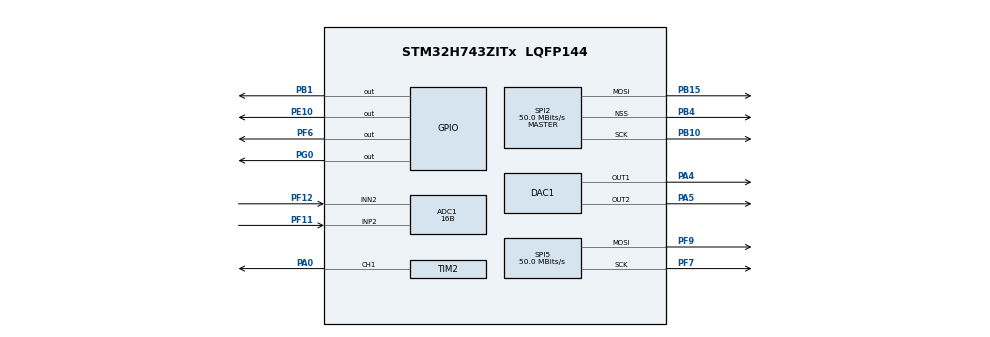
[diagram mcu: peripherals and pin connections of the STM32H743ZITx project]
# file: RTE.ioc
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ADC1.Channel-0\#ChannelRegularConversion=ADC_CHANNEL_2
ADC1.ClockPrescaler=ADC_CLOCK_ASYNC_DIV2
ADC1.ContinuousConvMode=ENABLE
ADC1.ConversionDataManagement=ADC_CONVERSIONDATA_DR
ADC1.DiscontinuousConvMode=DISABLE
ADC1.EOCSelection=ADC_EOC_SINGLE_CONV
ADC1.EnableAnalogWatchDog1=false
ADC1.EnableAnalogWatchDog2=false
ADC1.EnableAnalogWatchDog3=false
ADC1.EnableInjectedConversion=DISABLE
ADC1.EnableRegularConversion=ENABLE
ADC1.ExternalTrigConv=ADC_SOFTWARE_START
ADC1.ExternalTrigConvEdge=ADC_EXTERNALTRIGCONVEDGE_NONE
ADC1.LeftBitShift=ADC_LEFTBITSHIFT_NONE
ADC1.LowPowerAutoWait=DISABLE
ADC1.NbrOfConversion=1
ADC1.NbrOfConversionFlag=1
ADC1.OffsetNumber-0\#ChannelRegularConversion=ADC_OFFSET_NONE
ADC1.Overrun=ADC_OVR_DATA_PRESERVED
ADC1.OversamplingMode=DISABLE
ADC1.Rank-0\#ChannelRegularConversion=1
ADC1.Resolution=ADC_RESOLUTION_16B
ADC1.SamplingTime-0\#ChannelRegularConversion=ADC_SAMPLETIME_1CYCLE_5
ADC1.ScanConvMode=ADC_SCAN_DISABLE
ADC1.SingleDiff-0\#ChannelRegularConversion=ADC_DIFFERENTIAL_ENDED
ADC1.master=1
CORTEX_M7.CPU_DCache=Disabled
DAC1.DAC_Channel-DAC_OUT1=DAC_CHANNEL_1
DAC1.DAC_Channel-DAC_OUT2=DAC_CHANNEL_2
DAC1.DAC_Trigger-DAC_OUT1=DAC_TRIGGER_T2_TRGO
DAC1.DAC_Trigger-DAC_OUT2=DAC_TRIGGER_T2_TRGO
Mcu.Family=STM32H7
Mcu.Name=STM32H743ZITx
Mcu.Package=LQFP144
NVIC.PriorityGroup=NVIC_PRIORITYGROUP_4
NVIC.TIM2_IRQn=true\:0\:0\:true\:false\:true\:true\:true
PA0.Signal=S_TIM2_CH1
PA13\ (JTMS/SWDIO).Mode=Serial_Wire
PA13\ (JTMS/SWDIO).Signal=DEBUG_JTMS-SWDIO
PA14\ (JTCK/SWCLK).Mode=Serial_Wire
PA14\ (JTCK/SWCLK).Signal=DEBUG_JTCK-SWCLK
PA4.Signal=COMP_DAC11_group
PA5.Signal=COMP_DAC12_group
PB1.GPIO_ModeDefaultOutputPP=GPIO_MODE_OUTPUT_PP
PB1.GPIO_PuPd=GPIO_PULLDOWN
PB1.GPIO_Speed=GPIO_SPEED_FREQ_VERY_HIGH
PB1.Signal=GPIO_Output
PB10.Mode=TX_Only_Simplex_Unidirect_Master
PB10.Signal=SPI2_SCK
PB15.Mode=TX_Only_Simplex_Unidirect_Master
PB15.Signal=SPI2_MOSI
PB4\ (NJTRST).Mode=NSS_Signal_Hard_Output
PB4\ (NJTRST).Signal=SPI2_NSS
PE10.PinState=GPIO_PIN_SET
PE10.Signal=GPIO_Output
PF11.Mode=IN2-Differential
PF11.Signal=ADC1_INP2
PF12.Mode=IN2-Differential
PF12.Signal=ADC1_INN2
PF6.GPIO_Speed=GPIO_SPEED_FREQ_VERY_HIGH
PF6.Signal=GPIO_Output
PF7.Mode=TX_Only_Simplex_Unidirect_Master
PF7.Signal=SPI5_SCK
PF9.Mode=TX_Only_Simplex_Unidirect_Master
PF9.Signal=SPI5_MOSI
PG0.Signal=GPIO_Output
PH0-OSC_IN\ (PH0).Mode=HSE-External-Oscillator
PH0-OSC_IN\ (PH0).Signal=RCC_OSC_IN
PH1-OSC_OUT\ (PH1).Mode=HSE-External-Oscillator
PH1-OSC_OUT\ (PH1).Signal=RCC_OSC_OUT
ProjectManager.HeapSize=0x3000
ProjectManager.StackSize=0x400
ProjectManager.TargetToolchain=Makefile
RCC.ADCCLockSelection=RCC_ADCCLKSOURCE_PLL3
RCC.ADCFreq_Value=66666666.666666664
RCC.APB1Freq_Value=100000000
RCC.APB2Freq_Value=100000000
RCC.APB3Freq_Value=100000000
RCC.APB4Freq_Value=100000000
RCC.CortexFreq_Value=400000000
RCC.D1PPRE=RCC_APB3_DIV2
RCC.D2PPRE1=RCC_APB1_DIV2
RCC.D2PPRE2=RCC_APB2_DIV2
RCC.D3PPRE=RCC_APB4_DIV2
RCC.DIVM1=1
RCC.DIVM2=1
RCC.DIVM3=1
RCC.DIVN1=100
RCC.DIVN2=19
RCC.DIVN3=25
RCC.DIVP3=1
RCC.DIVR3=3
RCC.HCLKFreq_Value=200000000
RCC.HPRE=RCC_HCLK_DIV2
RCC.HSE_VALUE=8000000
RCC.PLL3FRACN=0
RCC.PLLFRACN=0
RCC.PLLSourceVirtual=RCC_PLLSOURCE_HSE
RCC.PWR_Regulator_Voltage_Scale=PWR_REGULATOR_VOLTAGE_SCALE1
RCC.RCC_TIM_PRescaler_Selection=RCC_TIMPRES_ACTIVATED
RCC.SPI123CLockSelection=RCC_SPI123CLKSOURCE_PLL3
RCC.SYSCLKFreq_VALUE=400000000
RCC.SYSCLKSource=RCC_SYSCLKSOURCE_PLLCLK
RCC.Spi45ClockSelection=RCC_SPI45CLKSOURCE_PLL3
RCC.USART234578CLockSelection=RCC_USART234578CLKSOURCE_PLL3
RCC.USBFreq_Value=400000000
SH.COMP_DAC11_group.0=DAC1_OUT1,DAC_OUT1
SH.COMP_DAC12_group.0=DAC1_OUT2,DAC_OUT2
SH.S_TIM2_CH1.0=TIM2_CH1,PWM Generation1 CH1
SPI2.BaudRatePrescaler=SPI_BAUDRATEPRESCALER_4
SPI2.CalculateBaudRate=50.0 MBits/s
SPI2.DataSize=SPI_DATASIZE_16BIT
SPI2.Direction=SPI_DIRECTION_2LINES_TXONLY
SPI2.MasterInterDataIdleness=SPI_MASTER_INTERDATA_IDLENESS_02CYCLE
SPI2.Mode=SPI_MODE_MASTER
SPI2.VirtualNSS=VM_NSSHARD
SPI2.VirtualType=VM_MASTER
SPI5.CLKPhase=SPI_PHASE_2EDGE
SPI5.CalculateBaudRate=50.0 MBits/s
SPI5.DataSize=SPI_DATASIZE_16BIT
SPI5.Direction=SPI_DIRECTION_2LINES_TXONLY
SPI5.MasterInterDataIdleness=SPI_MASTER_INTERDATA_IDLENESS_02CYCLE
SPI5.Mode=SPI_MODE_MASTER
SPI5.VirtualType=VM_MASTER
TIM2.Channel-PWM\ Generation1\ CH1=TIM_CHANNEL_1
TIM2.Pulse-PWM\ Generation1\ CH1=2
TIM2.TIM_MasterOutputTrigger=TIM_TRGO_UPDATE
VP_TIM2_VS_ClockSourceINT.Mode=Internal
board=custom

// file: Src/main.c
/* USER CODE BEGIN Header */
/**
 ******************************************************************************
 * @file           : main.c
 * @brief          : Main program body
 ******************************************************************************
 * @attention
 *
 * <h2><center>&copy; Copyright (c) 2021 STMicroelectronics.
 * All rights reserved.</center></h2>
 *
 * This software component is licensed by ST under BSD 3-Clause license,
 * the "License"; You may not use this file except in compliance with the
 * License. You may obtain a copy of the License at:
 *                        opensource.org/licenses/BSD-3-Clause
 *
 ******************************************************************************
 */
/* USER CODE END Header */
#include "main.h"
#include "adc.h"
#include "dac.h"
#include "gpio.h"
#include "spi.h"
#include "tim.h"

void SystemClock_Config(void);
void PeriphCommonClock_Config(void);

/* USER CODE BEGIN 0 */
void application();
void application_interupt();
void HAL_TIM_PeriodElapsedCallback(TIM_HandleTypeDef* htim)
{
    application_interupt();
}
/* USER CODE END 0 */

int main(void)
{

    /* MCU Configuration--------------------------------------------------------*/

    /* Reset of all peripherals, Initializes the Flash interface and the Systick. */
    HAL_Init();

    /* Configure the system clock */
    SystemClock_Config();

    /* Configure the peripherals common clocks */
    PeriphCommonClock_Config();

    /* Initialize all configured peripherals */
    MX_GPIO_Init();
    MX_DAC1_Init();
    MX_ADC1_Init();
    MX_TIM2_Init();
    MX_SPI2_Init();
    MX_SPI5_Init();
    /* USER CODE BEGIN 2 */
    application();
    /* USER CODE END 2 */

    /* Infinite loop */
    while (1) {

    }
}

void SystemClock_Config(void)
{
    RCC_OscInitTypeDef RCC_OscInitStruct = {0};
    RCC_ClkInitTypeDef RCC_ClkInitStruct = {0};

    /** Supply configuration update enable
     */
    HAL_PWREx_ConfigSupply(PWR_LDO_SUPPLY);
    /** Configure the main internal regulator output voltage
     */
    __HAL_PWR_VOLTAGESCALING_CONFIG(PWR_REGULATOR_VOLTAGE_SCALE1);

    while (!__HAL_PWR_GET_FLAG(PWR_FLAG_VOSRDY)) {
    }
    /** Macro to configure the PLL clock source
     */
    __HAL_RCC_PLL_PLLSOURCE_CONFIG(RCC_PLLSOURCE_HSE);
    /** Initializes the RCC Oscillators according to the specified parameters
     * in the RCC_OscInitTypeDef structure.
     */
    RCC_OscInitStruct.OscillatorType = RCC_OSCILLATORTYPE_HSE;
    RCC_OscInitStruct.HSEState       = RCC_HSE_ON;
    RCC_OscInitStruct.PLL.PLLState   = RCC_PLL_ON;
    RCC_OscInitStruct.PLL.PLLSource  = RCC_PLLSOURCE_HSE;
    RCC_OscInitStruct.PLL.PLLM       = 1;
    RCC_OscInitStruct.PLL.PLLN       = 100;
    RCC_OscInitStruct.PLL.PLLP       = 2;
    RCC_OscInitStruct.PLL.PLLQ       = 2;
    RCC_OscInitStruct.PLL.PLLR       = 2;
    RCC_OscInitStruct.PLL.PLLRGE     = RCC_PLL1VCIRANGE_3;
    RCC_OscInitStruct.PLL.PLLVCOSEL  = RCC_PLL1VCOWIDE;
    RCC_OscInitStruct.PLL.PLLFRACN   = 0;
    if (HAL_RCC_OscConfig(&RCC_OscInitStruct) != HAL_OK) {
        Error_Handler();
    }
    /** Initializes the CPU, AHB and APB buses clocks
     */
    RCC_ClkInitStruct.ClockType = RCC_CLOCKTYPE_HCLK | RCC_CLOCKTYPE_SYSCLK | RCC_CLOCKTYPE_PCLK1 |
        RCC_CLOCKTYPE_PCLK2 | RCC_CLOCKTYPE_D3PCLK1 | RCC_CLOCKTYPE_D1PCLK1;
    RCC_ClkInitStruct.SYSCLKSource   = RCC_SYSCLKSOURCE_PLLCLK;
    RCC_ClkInitStruct.SYSCLKDivider  = RCC_SYSCLK_DIV1;
    RCC_ClkInitStruct.AHBCLKDivider  = RCC_HCLK_DIV2;
    RCC_ClkInitStruct.APB3CLKDivider = RCC_APB3_DIV2;
    RCC_ClkInitStruct.APB1CLKDivider = RCC_APB1_DIV2;
    RCC_ClkInitStruct.APB2CLKDivider = RCC_APB2_DIV2;
    RCC_ClkInitStruct.APB4CLKDivider = RCC_APB4_DIV2;

    if (HAL_RCC_ClockConfig(&RCC_ClkInitStruct, FLASH_LATENCY_2) != HAL_OK) {
        Error_Handler();
    }
}

void PeriphCommonClock_Config(void)
{
    RCC_PeriphCLKInitTypeDef PeriphClkInitStruct = {0};

    /** Initializes the peripherals clock
     */
    PeriphClkInitStruct.PeriphClockSelection =
        RCC_PERIPHCLK_ADC | RCC_PERIPHCLK_SPI2 | RCC_PERIPHCLK_SPI5 | RCC_PERIPHCLK_TIM;
    PeriphClkInitStruct.PLL3.PLL3M           = 1;
    PeriphClkInitStruct.PLL3.PLL3N           = 25;
    PeriphClkInitStruct.PLL3.PLL3P           = 1;
    PeriphClkInitStruct.PLL3.PLL3Q           = 2;
    PeriphClkInitStruct.PLL3.PLL3R           = 3;
    PeriphClkInitStruct.PLL3.PLL3RGE         = RCC_PLL3VCIRANGE_3;
    PeriphClkInitStruct.PLL3.PLL3VCOSEL      = RCC_PLL3VCOWIDE;
    PeriphClkInitStruct.PLL3.PLL3FRACN       = 0;
    PeriphClkInitStruct.Spi123ClockSelection = RCC_SPI123CLKSOURCE_PLL3;
    PeriphClkInitStruct.Spi45ClockSelection  = RCC_SPI45CLKSOURCE_PLL3;
    PeriphClkInitStruct.AdcClockSelection    = RCC_ADCCLKSOURCE_PLL3;
    PeriphClkInitStruct.TIMPresSelection     = RCC_TIMPRES_ACTIVATED;

    if (HAL_RCCEx_PeriphCLKConfig(&PeriphClkInitStruct) != HAL_OK) {
        Error_Handler();
    }
}

void Error_Handler(void)
{
    __disable_irq();
    while (1) {
    }
}

/************************ (C) COPYRIGHT STMicroelectronics *****END OF FILE****/
